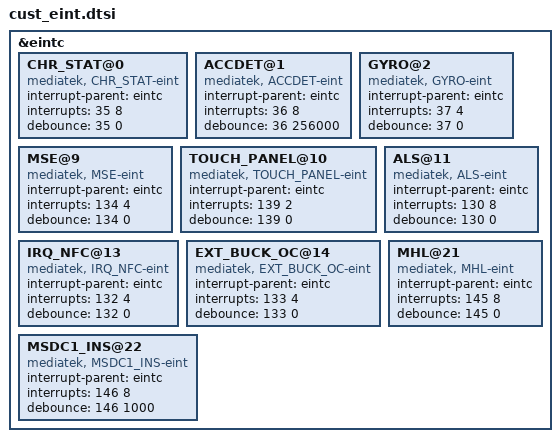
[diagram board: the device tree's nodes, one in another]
/*
 * Generated by MTK SP DrvGen Version 03.13.6 for MT6752. Copyright MediaTek Inc. (C) 2013.
 * Thu Dec 10 16:45:55 2015
 * Do Not Modify the File.
 */

/*************************
 * EINT DTSI File
*************************/

&eintc {
	CHR_STAT@0 {
		compatible = "mediatek, CHR_STAT-eint";
		interrupt-parent = <&eintc>;
		interrupts = <35 8>;
		debounce = <35 0>;
	};

	ACCDET@1 {
		compatible = "mediatek, ACCDET-eint";
		interrupt-parent = <&eintc>;
		interrupts = <36 8>;
		debounce = <36 256000>;
	};

	GYRO@2 {
		compatible = "mediatek, GYRO-eint";
		interrupt-parent = <&eintc>;
		interrupts = <37 4>;
		debounce = <37 0>;
	};

	MSE@9 {
		compatible = "mediatek, MSE-eint";
		interrupt-parent = <&eintc>;
		interrupts = <134 4>;
		debounce = <134 0>;
	};

	TOUCH_PANEL@10 {
		compatible = "mediatek, TOUCH_PANEL-eint";
		interrupt-parent = <&eintc>;
		interrupts = <139 2>;
		debounce = <139 0>;
	};

	ALS@11 {
		compatible = "mediatek, ALS-eint";
		interrupt-parent = <&eintc>;
		interrupts = <130 8>;
		debounce = <130 0>;
	};

	IRQ_NFC@13 {
		compatible = "mediatek, IRQ_NFC-eint";
		interrupt-parent = <&eintc>;
		interrupts = <132 4>;
		debounce = <132 0>;
	};

	EXT_BUCK_OC@14 {
		compatible = "mediatek, EXT_BUCK_OC-eint";
		interrupt-parent = <&eintc>;
		interrupts = <133 4>;
		debounce = <133 0>;
	};

	MHL@21 {
		compatible = "mediatek, MHL-eint";
		interrupt-parent = <&eintc>;
		interrupts = <145 8>;
		debounce = <145 0>;
	};

	MSDC1_INS@22 {
		compatible = "mediatek, MSDC1_INS-eint";
		interrupt-parent = <&eintc>;
		interrupts = <146 8>;
		debounce = <146 1000>;
	};

};
